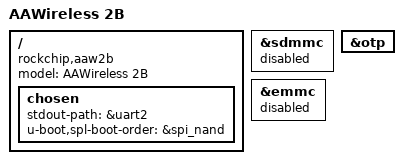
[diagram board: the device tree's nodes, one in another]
// SPDX-License-Identifier: (GPL-2.0+ OR MIT)
/*
 * Copyright (c) 2021 Fuzhou Rockchip Electronics Co., Ltd.
 */

/dts-v1/;

#include "rv1106.dtsi"
#include "rv1106-u-boot.dtsi"
#include <dt-bindings/input/input.h>

/ {
    model = "AAWireless 2B";
    compatible = "rockchip,aaw2b", "rockchip,rv1106";

    chosen {
        stdout-path = &uart2;
        u-boot,spl-boot-order = &spi_nand;
    };
};

&sdmmc {
    status = "disabled";
};

&emmc {
    status = "disabled";
};

&otp {
    u-boot,dm-spl;
    status = "okay";
};
